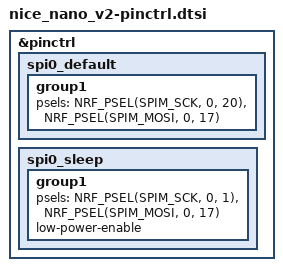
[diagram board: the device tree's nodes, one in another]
&pinctrl {
    spi0_default: spi0_default {
        group1 {
            psels = <NRF_PSEL(SPIM_SCK, 0, 20)>,
                    <NRF_PSEL(SPIM_MOSI, 0, 17)>;
        };
    };
    spi0_sleep: spi0_sleep {
        group1 {
            /* main role: configure P0.01 as SPI clock, P0.02 as SPI MOSI, P0.03 as SPI MISO */
            psels = <NRF_PSEL(SPIM_SCK, 0, 1)>,
                    <NRF_PSEL(SPIM_MOSI, 0, 17)>;
            low-power-enable;
        };
	};

};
